# VREF_1.0 register map
Vendor: Texas Instruments
Peripheral module from a debugger description file (folder mspm0gx218_gx207).
Registers are 32-bit, read-write, no defined reset value unless marked. A register's access mark holds for its fields unless they carry their own. Offsets are as the file gives them; lines under a group give offsets from that group; [hi:lo] are bit positions; {n}, {i} and the like mark numbered series; 'fields as' and 'values as' point back to an identical list; <NAME> marks a mode.

## VREF
0x800 VREF_GPRCM group
  0x00 VREF_PWREN — Power enable
    [0] ENABLE — Enable the power
      0=DISABLE (Disable Power); 1=ENABLE (Enable Power)
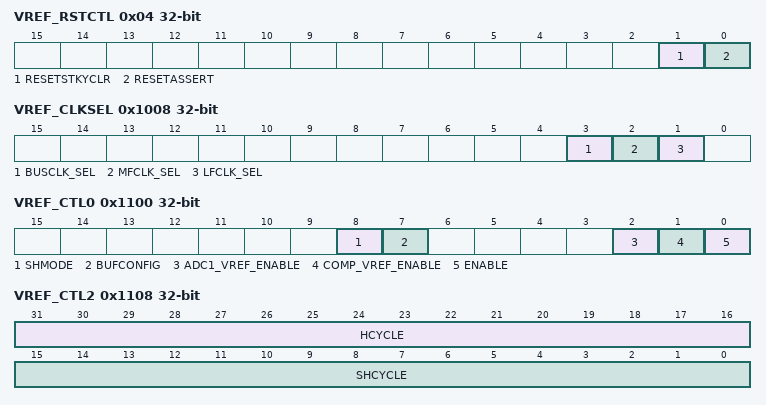
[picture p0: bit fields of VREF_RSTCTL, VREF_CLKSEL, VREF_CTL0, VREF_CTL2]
  0x04 VREF_RSTCTL — Reset Control
    [1] RESETSTKYCLR — Clear the RESETSTKY bit in the STAT register
      0=NOP (Writing 0 has no effect); 1=CLR (Clear reset sticky bit)
    [0] RESETASSERT — Assert reset to the peripheral
      0=NOP (Writing 0 has no effect); 1=ASSERT (Assert reset)
  0x14 VREF_STAT ro — Status Register
    [16] RESETSTKY — This bit indicates, if the peripheral was reset, since this bit was cleared by RESETSTKYCLR in the RSTCTL register
      0=NORES (The peripheral has not been reset since this bit was last cleared by RESETSTKYCLR in the RSTCTL register); 1=RESET (The peripheral was reset since the last bit clear)
0x1000 VREF_CLKDIV — Clock Divider
  [2:0] RATIO — Selects divide ratio of module clock to be used in sample and hold logic
0x1008 VREF_CLKSEL — Clock Selection
  [3] BUSCLK_SEL — Selects BUSCLK as clock source if enabled
  [2] MFCLK_SEL — Selects MFCLK as clock source if enabled
  [1] LFCLK_SEL — Selects LFCLK as clock source if enabled
0x1100 VREF_CTL0 — Control 0
  [8] SHMODE — This bit enable sample and hold mode
    0=DISABLE (Sample and hold mode is disable); 1=Enable (Sample and hold mode is enable)
  [7] BUFCONFIG — These bits configure output buffer.
    0=OUTPUT2P5V (Configure Output Buffer to 2.5v); 1=OUTPUT1P4V (Configure Output Buffer to 1.4v)
  [2] ADC1_VREF_ENABLE
    0=DISABLE (ADC1 VREF is disabled); 1=ENABLE (ADC1 VREF is enabled)
  [1] COMP_VREF_ENABLE — Comparator Vref Enable
    0=DISABLE (COMP VREF is disabled); 1=ENABLE (COMP VREF is enabled)
  [0] ENABLE — This bit enables the VREF module.
    0=DISABLE (VREF is disabled); 1=ENABLE (VREF is enabled)
0x1104 VREF_CTL1 ro — Control 1
  [0] READY — These bits defines status of VREF
    0=NOTRDY (VREF output is not ready); 1=RDY (VREF output is ready)
0x1108 VREF_CTL2 — Control 2
  [31:16] HCYCLE — Hold cycle count Total cycles of module clock for hold phase when VREF is working in sample and hold mode in STANDBY to save power. Please refer VREF section of datasheet for recommended values of sample and hold times.
    0=MINIMUM (smallest hold cycle); 0xFFFF=MAXIMUM (largest hold cycle)
  [15:0] SHCYCLE — Sample and Hold cycle count Total cycles of module clock for sample and hold phase when VREF is working in sample and hold mode in STANDBY to save power. This field should be greater than HCYCLE field. The difference between this field and HCYCLE gives the number of cycles of sample phase. Please refer VREF section of datasheet for recommended values of sample and hold times.
    0=MINIMUM (smallest sample and hold cycle count); 0xFFFF=MAXIMUM (largest sample and hold cycle)
